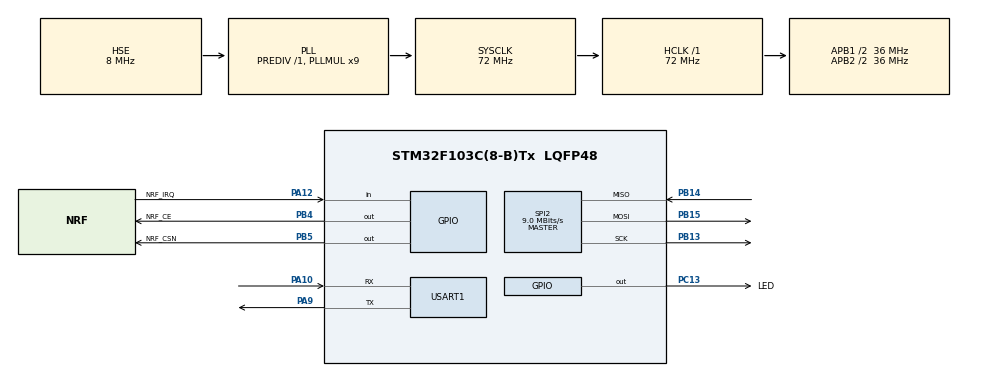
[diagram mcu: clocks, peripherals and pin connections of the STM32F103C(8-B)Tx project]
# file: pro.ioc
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Mcu.Family=STM32F1
Mcu.Name=STM32F103C(8-B)Tx
Mcu.Package=LQFP48
NVIC.PriorityGroup=NVIC_PRIORITYGROUP_3
NVIC.TIM3_IRQn=true\:2\:1\:true\:false\:true
NVIC.USART1_IRQn=true\:1\:1\:true\:false\:true
PA10.Mode=Asynchronous
PA10.Signal=USART1_RX
PA12.GPIO_Label=NRF_IRQ
PA12.Signal=GPIO_Input
PA13.Mode=Serial_Wire
PA13.Signal=SYS_JTMS-SWDIO
PA14.Mode=Serial_Wire
PA14.Signal=SYS_JTCK-SWCLK
PA9.Mode=Asynchronous
PA9.Signal=USART1_TX
PB13.Mode=Full_Duplex_Master
PB13.Signal=SPI2_SCK
PB14.Mode=Full_Duplex_Master
PB14.Signal=SPI2_MISO
PB15.Mode=Full_Duplex_Master
PB15.Signal=SPI2_MOSI
PB4.GPIO_Label=NRF_CE
PB4.PinState=GPIO_PIN_SET
PB4.Signal=GPIO_Output
PB5.GPIO_Label=NRF_CSN
PB5.PinState=GPIO_PIN_SET
PB5.Signal=GPIO_Output
PC13-TAMPER-RTC.GPIO_Label=LED
PC13-TAMPER-RTC.Signal=GPIO_Output
PD0-OSC_IN.Mode=HSE-External-Oscillator
PD0-OSC_IN.Signal=RCC_OSC_IN
PD1-OSC_OUT.Mode=HSE-External-Oscillator
PD1-OSC_OUT.Signal=RCC_OSC_OUT
ProjectManager.HeapSize=0x200
ProjectManager.StackSize=0x400
ProjectManager.TargetToolchain=MDK-ARM V5
RCC.AHBFreq_Value=72000000
RCC.APB1CLKDivider=RCC_HCLK_DIV2
RCC.APB1Freq_Value=36000000
RCC.APB1TimFreq_Value=72000000
RCC.APB2CLKDivider=RCC_HCLK_DIV2
RCC.APB2Freq_Value=36000000
RCC.APB2TimFreq_Value=72000000
RCC.HCLKFreq_Value=72000000
RCC.PLLMUL=RCC_PLL_MUL9
RCC.PLLSourceVirtual=RCC_PLLSOURCE_HSE
RCC.SYSCLKFreq_VALUE=72000000
RCC.SYSCLKSource=RCC_SYSCLKSOURCE_PLLCLK
RCC.USBFreq_Value=72000000
SPI2.BaudRatePrescaler=SPI_BAUDRATEPRESCALER_4
SPI2.CalculateBaudRate=9.0 MBits/s
SPI2.Direction=SPI_DIRECTION_2LINES
SPI2.Mode=SPI_MODE_MASTER
SPI2.VirtualType=VM_MASTER
TIM3.Period=50000-1
TIM3.Prescaler=43200-1
USART1.VirtualMode=VM_ASYNC
VP_TIM3_VS_ClockSourceINT.Mode=Internal
board=pro

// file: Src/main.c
/**
  ******************************************************************************
  * File Name          : main.c
  * Description        : Main program body
  ******************************************************************************
  *
  * COPYRIGHT(c) 2017 STMicroelectronics
  *
  * Redistribution and use in source and binary forms, with or without modification,
  * are permitted provided that the following conditions are met:
  *   1. Redistributions of source code must retain the above copyright notice,
  *      this list of conditions and the following disclaimer.
  *   2. Redistributions in binary form must reproduce the above copyright notice,
  *      this list of conditions and the following disclaimer in the documentation
  *      and/or other materials provided with the distribution.
  *   3. Neither the name of STMicroelectronics nor the names of its contributors
  *      may be used to endorse or promote products derived from this software
  *      without specific prior written permission.
  *
  * THIS SOFTWARE IS PROVIDED BY THE COPYRIGHT HOLDERS AND CONTRIBUTORS "AS IS"
  * AND ANY EXPRESS OR IMPLIED WARRANTIES, INCLUDING, BUT NOT LIMITED TO, THE
  * IMPLIED WARRANTIES OF MERCHANTABILITY AND FITNESS FOR A PARTICULAR PURPOSE ARE
  * DISCLAIMED. IN NO EVENT SHALL THE COPYRIGHT HOLDER OR CONTRIBUTORS BE LIABLE
  * FOR ANY DIRECT, INDIRECT, INCIDENTAL, SPECIAL, EXEMPLARY, OR CONSEQUENTIAL
  * DAMAGES (INCLUDING, BUT NOT LIMITED TO, PROCUREMENT OF SUBSTITUTE GOODS OR
  * SERVICES; LOSS OF USE, DATA, OR PROFITS; OR BUSINESS INTERRUPTION) HOWEVER
  * CAUSED AND ON ANY THEORY OF LIABILITY, WHETHER IN CONTRACT, STRICT LIABILITY,
  * OR TORT (INCLUDING NEGLIGENCE OR OTHERWISE) ARISING IN ANY WAY OUT OF THE USE
  * OF THIS SOFTWARE, EVEN IF ADVISED OF THE POSSIBILITY OF SUCH DAMAGE.
  *
  ******************************************************************************
  */
#include "main.h"
#include "stm32f1xx_hal.h"
#include "spi.h"
#include "tim.h"
#include "usart.h"
#include "gpio.h"

/* USER CODE BEGIN Includes */
#include "BSP_Main.h"
/* USER CODE END Includes */

/* USER CODE BEGIN PV */
/* Private variables ---------------------------------------------------------*/

/* USER CODE END PV */

void SystemClock_Config(void);
void Error_Handler(void);

/* USER CODE BEGIN PFP */
/* Private function prototypes -----------------------------------------------*/

/* USER CODE END PFP */

int main(void)
{

  /* MCU Configuration----------------------------------------------------------*/

  /* Reset of all peripherals, Initializes the Flash interface and the Systick. */
  HAL_Init();

  /* Configure the system clock */
  SystemClock_Config();

  /* Initialize all configured peripherals */
  MX_GPIO_Init();
  MX_USART1_UART_Init();
  MX_SPI2_Init();
  MX_TIM3_Init();

  /* USER CODE BEGIN 2 */
	BSP_Main();
  /* USER CODE END 2 */

  /* Infinite loop */
  while (1)
  {

  /* USER CODE BEGIN 3 */
		HAL_GPIO_TogglePin(LED_GPIO_Port,LED_Pin);
		HAL_Delay(500);

  }
  /* USER CODE END 3 */

}

/** System Clock Configuration
*/
void SystemClock_Config(void)
{

  RCC_OscInitTypeDef RCC_OscInitStruct;
  RCC_ClkInitTypeDef RCC_ClkInitStruct;

    /**Initializes the CPU, AHB and APB busses clocks
    */
  RCC_OscInitStruct.OscillatorType = RCC_OSCILLATORTYPE_HSE;
  RCC_OscInitStruct.HSEState = RCC_HSE_ON;
  RCC_OscInitStruct.HSEPredivValue = RCC_HSE_PREDIV_DIV1;
  RCC_OscInitStruct.HSIState = RCC_HSI_ON;
  RCC_OscInitStruct.PLL.PLLState = RCC_PLL_ON;
  RCC_OscInitStruct.PLL.PLLSource = RCC_PLLSOURCE_HSE;
  RCC_OscInitStruct.PLL.PLLMUL = RCC_PLL_MUL9;
  if (HAL_RCC_OscConfig(&RCC_OscInitStruct) != HAL_OK)
  {
    Error_Handler();
  }

    /**Initializes the CPU, AHB and APB busses clocks
    */
  RCC_ClkInitStruct.ClockType = RCC_CLOCKTYPE_HCLK|RCC_CLOCKTYPE_SYSCLK
                              |RCC_CLOCKTYPE_PCLK1|RCC_CLOCKTYPE_PCLK2;
  RCC_ClkInitStruct.SYSCLKSource = RCC_SYSCLKSOURCE_PLLCLK;
  RCC_ClkInitStruct.AHBCLKDivider = RCC_SYSCLK_DIV1;
  RCC_ClkInitStruct.APB1CLKDivider = RCC_HCLK_DIV2;
  RCC_ClkInitStruct.APB2CLKDivider = RCC_HCLK_DIV2;

  if (HAL_RCC_ClockConfig(&RCC_ClkInitStruct, FLASH_LATENCY_2) != HAL_OK)
  {
    Error_Handler();
  }

    /**Configure the Systick interrupt time
    */
  HAL_SYSTICK_Config(HAL_RCC_GetHCLKFreq()/1000);

    /**Configure the Systick
    */
  HAL_SYSTICK_CLKSourceConfig(SYSTICK_CLKSOURCE_HCLK);

  /* SysTick_IRQn interrupt configuration */
  HAL_NVIC_SetPriority(SysTick_IRQn, 0, 0);
}

void Error_Handler(void)
{
  while(1)
  {
  }
}

/************************ (C) COPYRIGHT STMicroelectronics *****END OF FILE****/
